VERSION ""

NS_ :

BS_:

BU_: MCU2 MCU1 HCU

BO_ 3221225472 VECTOR__INDEPENDENT_SIG_MSG: 0 Vector__XXX
 SG_ MCU1_iqFdb : 0|16@1+ (1,-10000) [0|0] "" Vector__XXX
 SG_ MCU1_MLoop : 0|8@1+ (1,0) [0|0] "" Vector__XXX
 SG_ MCU1_FreqCoder : 0|16@1+ (0.1,0) [0|0] "" Vector__XXX
 SG_ MCU2_DcVolInst : 0|8@1+ (5,0) [0|0] "V" Vector__XXX
 SG_ MCU2_FaultCodeTemp : 0|8@1+ (1,0) [0|0] "" Vector__XXX
 SG_ MCU1_DcVolInst : 0|8@1+ (5,0) [0|0] "V" Vector__XXX
 SG_ MCU1_FaultCodeTemp : 0|8@1+ (1,0) [0|0] "" Vector__XXX

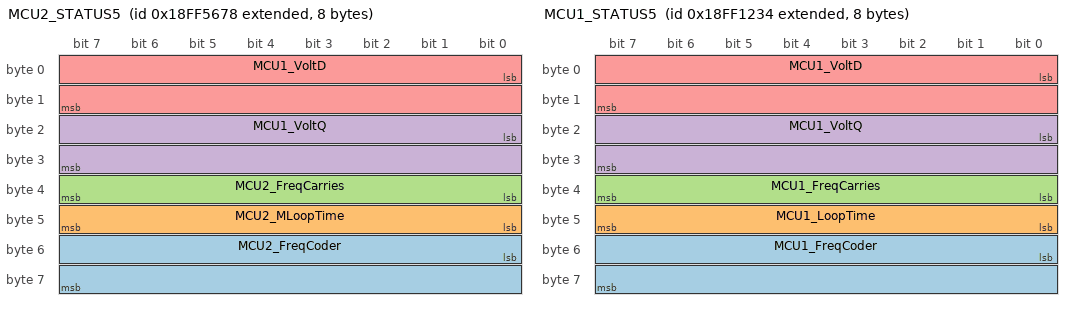
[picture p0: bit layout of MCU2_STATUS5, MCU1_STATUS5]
BO_ 2566870648 MCU2_STATUS5: 8 Vector__XXX
 SG_ MCU2_FreqCoder : 48|16@1+ (0.1,0) [0|0] "" Vector__XXX
 SG_ MCU2_MLoopTime : 40|8@1+ (1,0) [0|0] "" Vector__XXX
 SG_ MCU2_FreqCarries : 32|8@1+ (0.1,0) [0|0] "Khz" Vector__XXX
 SG_ MCU1_VoltQ : 16|16@1+ (1,-30000) [0|0] "" Vector__XXX
 SG_ MCU1_VoltD : 0|16@1+ (1,-30000) [0|0] "" Vector__XXX

BO_ 2566853172 MCU1_STATUS5: 8 Vector__XXX
 SG_ MCU1_FreqCoder : 48|16@1+ (0.1,0) [0|0] "" Vector__XXX
 SG_ MCU1_LoopTime : 40|8@1+ (1,0) [0|0] "" Vector__XXX
 SG_ MCU1_FreqCarries : 32|8@1+ (1,0) [0|0] "" Vector__XXX
 SG_ MCU1_VoltQ : 16|16@1+ (1,-30000) [0|0] "" Vector__XXX
 SG_ MCU1_VoltD : 0|16@1+ (1,-30000) [0|0] "" Vector__XXX

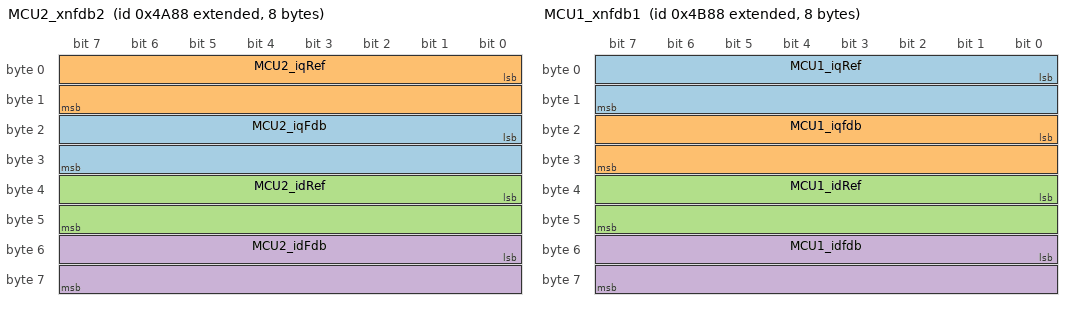
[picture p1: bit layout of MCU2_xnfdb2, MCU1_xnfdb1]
BO_ 2147502728 MCU2_xnfdb2: 8 Vector__XXX
 SG_ MCU2_iqFdb : 16|16@1+ (1,-10000) [0|0] "" Vector__XXX
 SG_ MCU2_iqRef : 0|16@1+ (1,-10000) [0|0] "" Vector__XXX
 SG_ MCU2_idRef : 32|16@1+ (1,-10000) [0|0] "" Vector__XXX
 SG_ MCU2_idFdb : 48|16@1+ (1,-10000) [0|0] "" Vector__XXX

BO_ 2147502984 MCU1_xnfdb1: 8 Vector__XXX
 SG_ MCU1_iqRef : 0|16@1- (1,-10000) [0|0] "" Vector__XXX
 SG_ MCU1_iqfdb : 16|16@1- (1,-10000) [0|0] "" Vector__XXX
 SG_ MCU1_idRef : 32|16@1+ (1,-10000) [0|0] "" Vector__XXX
 SG_ MCU1_idfdb : 48|16@1+ (1,-10000) [0|0] "" Vector__XXX

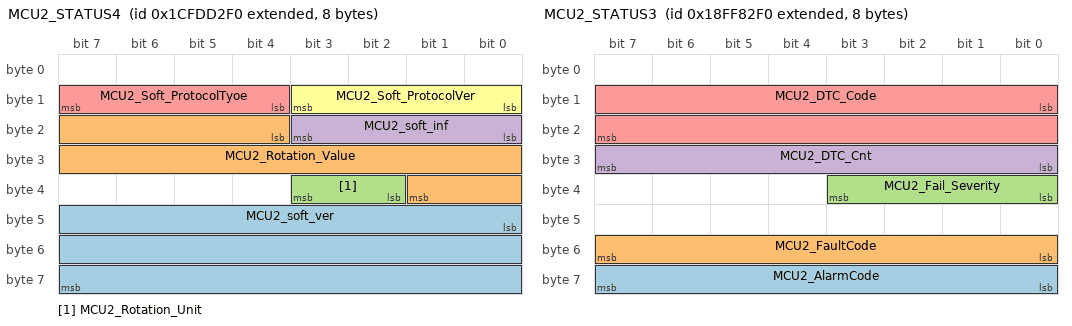
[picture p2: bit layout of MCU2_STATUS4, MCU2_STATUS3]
BO_ 2633880304 MCU2_STATUS4: 8 MCU2
 SG_ MCU2_soft_ver : 40|24@1+ (1,0) [0|16777215] ""  HCU
 SG_ MCU2_Rotation_Value : 20|14@1+ (0.1,0) [0|0] ""  HCU
 SG_ MCU2_Rotation_Unit : 34|2@1+ (1,0) [0|3] ""  HCU
 SG_ MCU2_soft_inf : 16|4@1+ (1,0) [0|15] ""  HCU
 SG_ MCU2_Soft_ProtocolTyoe : 12|4@1+ (1,0) [0|15] ""  HCU
 SG_ MCU2_Soft_ProtocolVer : 8|4@1+ (0.1,2) [0|0] ""  HCU

BO_ 2566882032 MCU2_STATUS3: 8 MCU2
 SG_ MCU2_AlarmCode : 56|8@1+ (1,0) [0|0] ""  HCU
 SG_ MCU2_FaultCode : 48|8@1+ (1,0) [0|0] ""  HCU
 SG_ MCU2_Fail_Severity : 32|4@1+ (1,0) [0|15] ""  HCU
 SG_ MCU2_DTC_Cnt : 24|8@1+ (1,0) [0|255] ""  HCU
 SG_ MCU2_DTC_Code : 8|16@1+ (1,0) [0|65535] ""  HCU

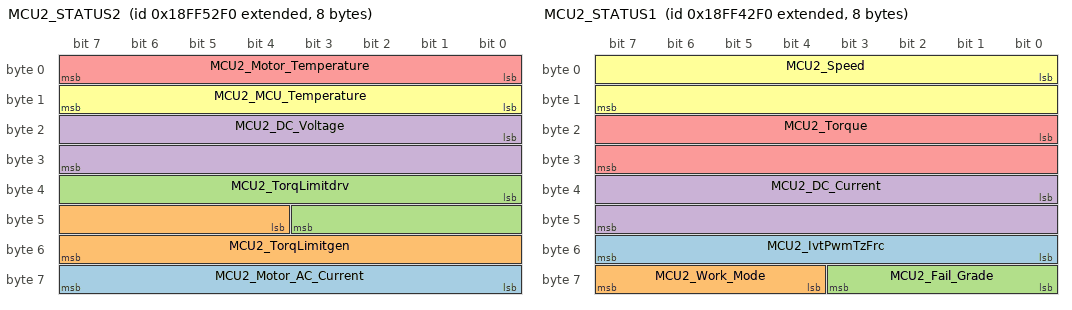
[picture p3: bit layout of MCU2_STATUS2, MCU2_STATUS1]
BO_ 2566869744 MCU2_STATUS2: 8 MCU2
 SG_ MCU2_Motor_AC_Current : 56|8@1+ (3,0) [0|765] ""  HCU
 SG_ MCU2_TorqLimitgen : 44|12@1+ (1,0) [0|4095] "NM"  HCU
 SG_ MCU2_TorqLimitdrv : 32|12@1+ (1,0) [0|4095] "NM"  HCU
 SG_ MCU2_DC_Voltage : 16|16@1+ (1,0) [0|65535] "V"  HCU
 SG_ MCU2_Motor_Temperature : 0|8@1+ (1,-40) [-40|215] "degree Celsius"  HCU
 SG_ MCU2_MCU_Temperature : 8|8@1+ (1,-40) [-40|215] "degree Celsius"  HCU

BO_ 2566865648 MCU2_STATUS1: 8 MCU2
 SG_ MCU2_IvtPwmTzFrc : 48|8@1+ (1,0) [0|0] "" Vector__XXX
 SG_ MCU2_Work_Mode : 60|4@1+ (1,0) [0|15] ""  HCU
 SG_ MCU2_Fail_Grade : 56|4@1+ (1,0) [0|15] ""  HCU
 SG_ MCU2_DC_Current : 32|16@1+ (1,-1000) [-1000|64535] "A"  HCU
 SG_ MCU2_Torque : 16|16@1+ (1,-3200) [-3200|62335] "Nm"  HCU
 SG_ MCU2_Speed : 0|16@1+ (1,-6000) [-6000|59535] "rpm"  HCU

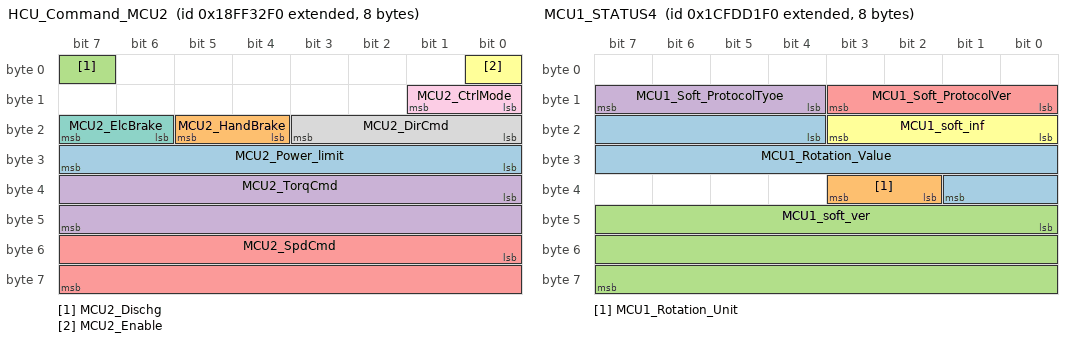
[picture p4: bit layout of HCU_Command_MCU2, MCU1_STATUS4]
BO_ 2566861552 HCU_Command_MCU2: 8 HCU
 SG_ MCU2_Power_limit : 24|8@1+ (1,0) [0|255] "Kw"  MCU2
 SG_ MCU2_HandBrake : 20|2@1+ (1,0) [0|3] ""  MCU2
 SG_ MCU2_Dischg : 7|1@1+ (1,0) [0|1] ""  MCU2
 SG_ MCU2_TorqCmd : 32|16@1+ (1,-3200) [-3200|62335] "Nm"  MCU2
 SG_ MCU2_SpdCmd : 48|16@1+ (1,-6000) [-6000|59535] "rpm"  MCU2
 SG_ MCU2_Enable : 0|1@1+ (1,0) [0|1] ""  MCU2
 SG_ MCU2_ElcBrake : 22|2@1+ (1,0) [0|3] ""  MCU2
 SG_ MCU2_DirCmd : 16|4@1+ (1,0) [0|15] ""  MCU2
 SG_ MCU2_CtrlMode : 8|2@1+ (1,0) [0|3] ""  MCU2

BO_ 2633880048 MCU1_STATUS4: 8 MCU1
 SG_ MCU1_Rotation_Value : 20|14@1+ (0.1,0) [0|0] ""  HCU
 SG_ MCU1_Rotation_Unit : 34|2@1+ (1,0) [0|3] ""  HCU
 SG_ MCU1_soft_ver : 40|24@1+ (1,0) [0|16777215] ""  HCU
 SG_ MCU1_Soft_ProtocolTyoe : 12|4@1+ (1,0) [0|15] ""  HCU
 SG_ MCU1_Soft_ProtocolVer : 8|4@1+ (0.1,2) [0|0] ""  HCU
 SG_ MCU1_soft_inf : 16|4@1+ (1,0) [0|15] ""  HCU

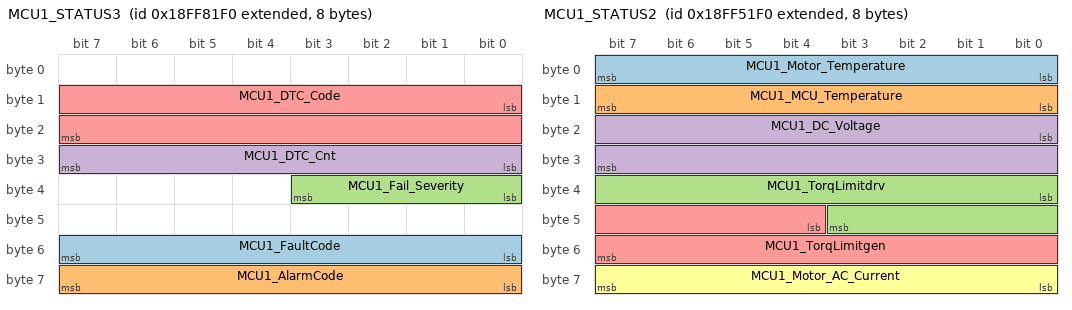
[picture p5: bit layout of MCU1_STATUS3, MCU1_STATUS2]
BO_ 2566881776 MCU1_STATUS3: 8 MCU1
 SG_ MCU1_FaultCode : 48|8@1+ (1,0) [0|0] ""  HCU
 SG_ MCU1_AlarmCode : 56|8@1+ (1,0) [0|0] ""  HCU
 SG_ MCU1_Fail_Severity : 32|4@1+ (1,0) [0|15] ""  HCU
 SG_ MCU1_DTC_Cnt : 24|8@1+ (1,0) [0|255] ""  HCU
 SG_ MCU1_DTC_Code : 8|16@1+ (1,0) [0|65535] ""  HCU

BO_ 2566869488 MCU1_STATUS2: 8 MCU1
 SG_ MCU1_Motor_Temperature : 0|8@1+ (1,-40) [-40|215] "degree Celsius"  HCU
 SG_ MCU1_MCU_Temperature : 8|8@1+ (1,-40) [-40|215] "degree Celsius"  HCU
 SG_ MCU1_TorqLimitdrv : 32|12@1+ (1,0) [0|4095] "NM"  HCU
 SG_ MCU1_DC_Voltage : 16|16@1+ (1,0) [0|65535] "V"  HCU
 SG_ MCU1_TorqLimitgen : 44|12@1+ (1,0) [0|4095] "NM"  HCU
 SG_ MCU1_Motor_AC_Current : 56|8@1+ (3,0) [0|765] ""  HCU

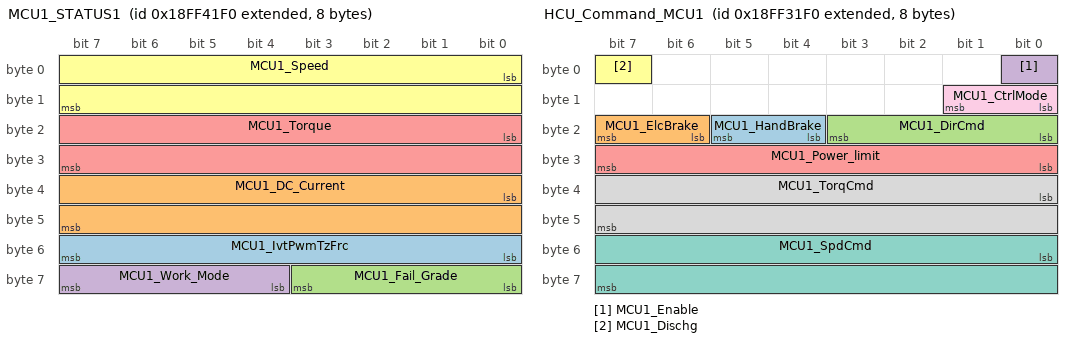
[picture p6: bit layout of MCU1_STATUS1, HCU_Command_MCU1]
BO_ 2566865392 MCU1_STATUS1: 8 MCU1
 SG_ MCU1_IvtPwmTzFrc : 48|8@1+ (1,0) [0|0] "" Vector__XXX
 SG_ MCU1_DC_Current : 32|16@1+ (1,-1000) [-1000|64535] "A"  HCU
 SG_ MCU1_Fail_Grade : 56|4@1+ (1,0) [0|15] ""  HCU
 SG_ MCU1_Work_Mode : 60|4@1+ (1,0) [0|15] ""  HCU
 SG_ MCU1_Torque : 16|16@1+ (1,-3200) [-3200|62335] "Nm"  HCU
 SG_ MCU1_Speed : 0|16@1+ (1,-6000) [-6000|59535] "rpm"  HCU

BO_ 2566861296 HCU_Command_MCU1: 8 HCU
 SG_ MCU1_HandBrake : 20|2@1+ (1,0) [0|3] ""  MCU1
 SG_ MCU1_ElcBrake : 22|2@1+ (1,0) [0|3] ""  MCU1
 SG_ MCU1_DirCmd : 16|4@1+ (1,0) [0|15] ""  MCU1
 SG_ MCU1_Enable : 0|1@1+ (1,0) [0|1] ""  MCU1
 SG_ MCU1_Power_limit : 24|8@1+ (1,0) [0|255] "Kw"  MCU1
 SG_ MCU1_Dischg : 7|1@1+ (1,0) [0|1] ""  MCU1
 SG_ MCU1_SpdCmd : 48|16@1+ (1,-6000) [-6000|59535] "rpm"  MCU1
 SG_ MCU1_TorqCmd : 32|16@1+ (1,-3200) [-3200|62335] "Nm"  MCU1
 SG_ MCU1_CtrlMode : 8|2@1+ (1,0) [0|3] ""  MCU1

CM_ BO_ 3221225472 "This is a message for not used signals, created by Vector CANdb++ DBC OLE DB Provider.";
CM_ BO_ 2633880304 " period 5000ms";
CM_ SG_ 2633880304 MCU2_soft_ver "0 = INIT
1 = LV_PWR_UP
2 = HV_PWR_UP
3 = Idle
4 = Speed Control
5 = Torque Control
6 = SHUTDWN(active capacitor discharge)
7 = LV_PWR_DWN
8 = FAULT";
CM_ SG_ 2633880304 MCU2_soft_inf "0 = INIT
1 = LV_PWR_UP
2 = HV_PWR_UP
3 = Idle
4 = Speed Control
5 = Torque Control
6 = SHUTDWN(active capacitor discharge)
7 = LV_PWR_DWN
8 = FAULT";
CM_ SG_ 2633880304 MCU2_Soft_ProtocolTyoe "0 = INIT
1 = LV_PWR_UP
2 = HV_PWR_UP
3 = Idle
4 = Speed Control
5 = Torque Control
6 = SHUTDWN(active capacitor discharge)
7 = LV_PWR_DWN
8 = FAULT";
CM_ SG_ 2633880304 MCU2_Soft_ProtocolVer "0 = INIT
1 = LV_PWR_UP
2 = HV_PWR_UP
3 = Idle
4 = Speed Control
5 = Torque Control
6 = SHUTDWN(active capacitor discharge)
7 = LV_PWR_DWN
8 = FAULT";
CM_ BO_ 2566882032 " period 1000ms";
CM_ SG_ 2566882032 MCU2_Fail_Severity "0 = No Fault
1 = Warning(degraded)
2 = Fault(zero torque output)
3 = Fault(shut down MCU)
4 = Serious Fault(need to stop the vehicle)";
CM_ BO_ 2566869744 " period 10ms";
CM_ BO_ 2566865648 " period 10ms";
CM_ SG_ 2566865648 MCU2_Work_Mode "0 = Ready（上电完成 MCU 已开管不 控制）
1 = Enable（上电完成，MCU 未开管） 
2 = PowerUp（低压上电，准备上高压 或者高压上电过程中） 
3 = Error(错误)
4 = 防溜坡控制状态
5 = 转速模式扭矩受限
6 = 扭矩模式转速受限
7 = 快速下电中
8 = 扭矩控制
9 = 速度控制";
CM_ SG_ 2566865648 MCU2_Fail_Grade "0 = No Fault
1 = Warning(degraded)
2 = Fault(zero torque output)
3 = Fault(shut down MCU)
4 = Serious Fault(need to stop the vehicle)";
CM_ SG_ 2566865648 MCU2_Torque "转矩矩大于0为转矩方向与发动机转向相同";
CM_ SG_ 2566865648 MCU2_Speed "电机转速正负表示电机转向，转速为正时与发动机正常转动方向一致";
CM_ BO_ 2566861552 "Period 10ms";
CM_ SG_ 2566861552 MCU2_Power_limit "0 = Standby
1 = Speed Control
2 = Torque Control
3 = Active Discharge";
CM_ SG_ 2566861552 MCU2_HandBrake "0;未拉手刹
1：拉手刹";
CM_ SG_ 2566861552 MCU2_Dischg "00:空档位
01：前进档位
10：后退档位";
CM_ SG_ 2566861552 MCU2_Enable "0 = disable
1 = enable";
CM_ SG_ 2566861552 MCU2_ElcBrake "0:未踩脚刹
1：踩脚刹";
CM_ SG_ 2566861552 MCU2_DirCmd "00:空档位
01：前进档位
10：后退档位";
CM_ SG_ 2566861552 MCU2_CtrlMode "0 = Standby
1 = Speed Control
2 = Torque Control
3 = Active Discharge";
CM_ BO_ 2633880048 " period 5000ms";
CM_ SG_ 2633880048 MCU1_soft_ver "0 = INIT
1 = LV_PWR_UP
2 = HV_PWR_UP
3 = Idle
4 = Speed Control
5 = Torque Control
6 = SHUTDWN(active capacitor discharge)
7 = LV_PWR_DWN
8 = FAULT";
CM_ SG_ 2633880048 MCU1_Soft_ProtocolTyoe "0 = INIT
1 = LV_PWR_UP
2 = HV_PWR_UP
3 = Idle
4 = Speed Control
5 = Torque Control
6 = SHUTDWN(active capacitor discharge)
7 = LV_PWR_DWN
8 = FAULT";
CM_ SG_ 2633880048 MCU1_Soft_ProtocolVer "0 = INIT
1 = LV_PWR_UP
2 = HV_PWR_UP
3 = Idle
4 = Speed Control
5 = Torque Control
6 = SHUTDWN(active capacitor discharge)
7 = LV_PWR_DWN
8 = FAULT";
CM_ SG_ 2633880048 MCU1_soft_inf "0 = INIT
1 = LV_PWR_UP
2 = HV_PWR_UP
3 = Idle
4 = Speed Control
5 = Torque Control
6 = SHUTDWN(active capacitor discharge)
7 = LV_PWR_DWN
8 = FAULT";
CM_ BO_ 2566881776 " period 100ms";
CM_ SG_ 2566881776 MCU1_Fail_Severity "0 = No Fault
1 = Warning(degraded)
2 = Fault(zero torque output)
3 = Fault(shut down MCU)
4 = Serious Fault(need to stop the vehicle)";
CM_ BO_ 2566869488 " period 10ms";
CM_ BO_ 2566865392 " period 10ms";
CM_ SG_ 2566865392 MCU1_Fail_Grade "0 = No Fault
1 = Warning(degraded)
2 = Fault(zero torque output)
3 = Fault(shut down MCU)
4 = Serious Fault(need to stop the vehicle)";
CM_ SG_ 2566865392 MCU1_Work_Mode "0 = Ready（上电完成 MCU 已开管不 控制）
1 = Enable（上电完成，MCU 未开管） 
2 = PowerUp（低压上电，准备上高压 或者高压上电过程中） 
3 = Error(错误)
4 = 防溜坡控制状态
5 = 转速模式扭矩受限
6 = 扭矩模式转速受限
7 = 快速下电中
8 = 扭矩控制
9 = 速度控制";
CM_ SG_ 2566865392 MCU1_Torque "转矩矩大于0为转矩方向与发动机转向相同";
CM_ SG_ 2566865392 MCU1_Speed "电机转速正负表示电机转向，转速为正时与发动机正常转动方向一致";
CM_ BO_ 2566861296 "Period 10ms";
CM_ SG_ 2566861296 MCU1_HandBrake "0;未拉手刹
1：拉手刹";
CM_ SG_ 2566861296 MCU1_ElcBrake "0:未踩脚刹
1：踩脚刹";
CM_ SG_ 2566861296 MCU1_DirCmd "00:空档位
01：前进档位
10：后退档位";
CM_ SG_ 2566861296 MCU1_Enable "0 = disable
1 = enable";
CM_ SG_ 2566861296 MCU1_Power_limit "0 = Standby
1 = Speed Control
2 = Torque Control
3 = Active Discharge";
CM_ SG_ 2566861296 MCU1_Dischg "00:空档位
01：前进档位
10：后退档位";
CM_ SG_ 2566861296 MCU1_CtrlMode "0 = Standby
1 = Speed Control
2 = Torque Control
3 = Active Discharge";
